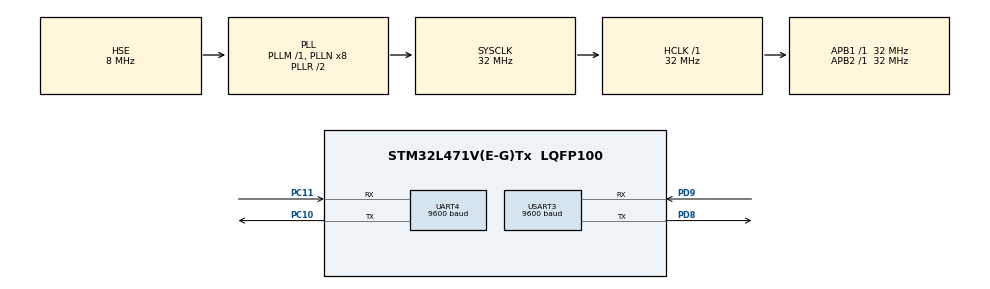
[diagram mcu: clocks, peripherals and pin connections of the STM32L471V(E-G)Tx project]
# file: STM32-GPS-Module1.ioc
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Dma.Request0=UART4_RX
Dma.UART4_RX.0.Direction=DMA_PERIPH_TO_MEMORY
Dma.UART4_RX.0.Instance=DMA2_Channel5
Dma.UART4_RX.0.MemDataAlignment=DMA_MDATAALIGN_BYTE
Dma.UART4_RX.0.MemInc=DMA_MINC_ENABLE
Dma.UART4_RX.0.Mode=DMA_CIRCULAR
Dma.UART4_RX.0.PeriphDataAlignment=DMA_PDATAALIGN_BYTE
Dma.UART4_RX.0.PeriphInc=DMA_PINC_DISABLE
Dma.UART4_RX.0.Priority=DMA_PRIORITY_VERY_HIGH
Mcu.Family=STM32L4
Mcu.Name=STM32L471V(E-G)Tx
Mcu.Package=LQFP100
NVIC.DMA2_Channel5_IRQn=true\:0\:0\:false\:false\:true\:false\:true\:true
NVIC.PriorityGroup=NVIC_PRIORITYGROUP_4
PC10.Mode=Asynchronous
PC10.Signal=UART4_TX
PC11.Mode=Asynchronous
PC11.Signal=UART4_RX
PC14-OSC32_IN\ (PC14).Mode=LSE-External-Clock-Source
PC14-OSC32_IN\ (PC14).Signal=RCC_OSC32_IN
PD8.Mode=Asynchronous
PD8.Signal=USART3_TX
PD9.Mode=Asynchronous
PD9.Signal=USART3_RX
PH0-OSC_IN\ (PH0).Mode=HSE-External-Oscillator
PH0-OSC_IN\ (PH0).Signal=RCC_OSC_IN
PH1-OSC_OUT\ (PH1).Mode=HSE-External-Oscillator
PH1-OSC_OUT\ (PH1).Signal=RCC_OSC_OUT
ProjectManager.HeapSize=0x200
ProjectManager.StackSize=0x400
ProjectManager.TargetToolchain=STM32CubeIDE
RCC.ADCFreq_Value=32000000
RCC.AHBFreq_Value=32000000
RCC.APB1Freq_Value=32000000
RCC.APB1TimFreq_Value=32000000
RCC.APB2Freq_Value=32000000
RCC.APB2TimFreq_Value=32000000
RCC.CortexFreq_Value=32000000
RCC.HCLKFreq_Value=32000000
RCC.HSE_VALUE=8000000
RCC.HSI_VALUE=16000000
RCC.LSE_VALUE=32768
RCC.MSI_VALUE=4000000
RCC.PLLSourceVirtual=RCC_PLLSOURCE_HSE
RCC.SYSCLKFreq_VALUE=32000000
RCC.SYSCLKSource=RCC_SYSCLKSOURCE_PLLCLK
RCC.VCOOutputFreq_Value=64000000
UART4.BaudRate=9600
USART3.BaudRate=9600
USART3.VirtualMode-Asynchronous=VM_ASYNC
board=custom

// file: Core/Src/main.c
/* USER CODE BEGIN Header */
/**
  ******************************************************************************
  * @file           : main.c
  * @brief          : Main program body
  ******************************************************************************
  * @attention
  *
  * Copyright (c) 2026 STMicroelectronics.
  * All rights reserved.
  *
  * This software is licensed under terms that can be found in the LICENSE file
  * in the root directory of this software component.
  * If no LICENSE file comes with this software, it is provided AS-IS.
  *
  ******************************************************************************
  */
/* USER CODE END Header */
#include "main.h"

/* USER CODE BEGIN Includes */
#include "gps.h"
/* USER CODE END Includes */

/* USER CODE BEGIN PTD */
GPS_t gps;
/* USER CODE END PTD */

UART_HandleTypeDef huart4;
UART_HandleTypeDef huart3;
DMA_HandleTypeDef hdma_uart4_rx;

void SystemClock_Config(void);
static void MX_GPIO_Init(void);
static void MX_DMA_Init(void);
static void MX_UART4_Init(void);
static void MX_USART3_UART_Init(void);

int main(void)
{

  /* MCU Configuration--------------------------------------------------------*/

  /* Reset of all peripherals, Initializes the Flash interface and the Systick. */
  HAL_Init();

  /* Configure the system clock */
  SystemClock_Config();

  /* Initialize all configured peripherals */
  MX_GPIO_Init();
  MX_DMA_Init();
  MX_UART4_Init();
  MX_USART3_UART_Init();
  /* USER CODE BEGIN 2 */
  GPS_Init(&gps, &huart4, &huart3);

  /* USER CODE END 2 */

  /* Infinite loop */
  /* USER CODE BEGIN WHILE */
  while (1)
  {
	  GPS_Task(&gps);

    /* USER CODE END WHILE */

  }
}

void SystemClock_Config(void)
{
  RCC_OscInitTypeDef RCC_OscInitStruct = {0};
  RCC_ClkInitTypeDef RCC_ClkInitStruct = {0};

  /** Configure the main internal regulator output voltage
  */
  if (HAL_PWREx_ControlVoltageScaling(PWR_REGULATOR_VOLTAGE_SCALE1) != HAL_OK)
  {
    Error_Handler();
  }

  /** Initializes the RCC Oscillators according to the specified parameters
  * in the RCC_OscInitTypeDef structure.
  */
  RCC_OscInitStruct.OscillatorType = RCC_OSCILLATORTYPE_HSE;
  RCC_OscInitStruct.HSEState = RCC_HSE_ON;
  RCC_OscInitStruct.PLL.PLLState = RCC_PLL_ON;
  RCC_OscInitStruct.PLL.PLLSource = RCC_PLLSOURCE_HSE;
  RCC_OscInitStruct.PLL.PLLM = 1;
  RCC_OscInitStruct.PLL.PLLN = 8;
  RCC_OscInitStruct.PLL.PLLP = RCC_PLLP_DIV7;
  RCC_OscInitStruct.PLL.PLLQ = RCC_PLLQ_DIV2;
  RCC_OscInitStruct.PLL.PLLR = RCC_PLLR_DIV2;
  if (HAL_RCC_OscConfig(&RCC_OscInitStruct) != HAL_OK)
  {
    Error_Handler();
  }

  /** Initializes the CPU, AHB and APB buses clocks
  */
  RCC_ClkInitStruct.ClockType = RCC_CLOCKTYPE_HCLK|RCC_CLOCKTYPE_SYSCLK
                              |RCC_CLOCKTYPE_PCLK1|RCC_CLOCKTYPE_PCLK2;
  RCC_ClkInitStruct.SYSCLKSource = RCC_SYSCLKSOURCE_PLLCLK;
  RCC_ClkInitStruct.AHBCLKDivider = RCC_SYSCLK_DIV1;
  RCC_ClkInitStruct.APB1CLKDivider = RCC_HCLK_DIV1;
  RCC_ClkInitStruct.APB2CLKDivider = RCC_HCLK_DIV1;

  if (HAL_RCC_ClockConfig(&RCC_ClkInitStruct, FLASH_LATENCY_1) != HAL_OK)
  {
    Error_Handler();
  }
}

static void MX_UART4_Init(void)
{

  huart4.Instance = UART4;
  huart4.Init.BaudRate = 9600;
  huart4.Init.WordLength = UART_WORDLENGTH_8B;
  huart4.Init.StopBits = UART_STOPBITS_1;
  huart4.Init.Parity = UART_PARITY_NONE;
  huart4.Init.Mode = UART_MODE_TX_RX;
  huart4.Init.HwFlowCtl = UART_HWCONTROL_NONE;
  huart4.Init.OverSampling = UART_OVERSAMPLING_16;
  huart4.Init.OneBitSampling = UART_ONE_BIT_SAMPLE_DISABLE;
  huart4.AdvancedInit.AdvFeatureInit = UART_ADVFEATURE_NO_INIT;
  if (HAL_UART_Init(&huart4) != HAL_OK)
  {
    Error_Handler();
  }

}

static void MX_USART3_UART_Init(void)
{

  huart3.Instance = USART3;
  huart3.Init.BaudRate = 9600;
  huart3.Init.WordLength = UART_WORDLENGTH_8B;
  huart3.Init.StopBits = UART_STOPBITS_1;
  huart3.Init.Parity = UART_PARITY_NONE;
  huart3.Init.Mode = UART_MODE_TX_RX;
  huart3.Init.HwFlowCtl = UART_HWCONTROL_NONE;
  huart3.Init.OverSampling = UART_OVERSAMPLING_16;
  huart3.Init.OneBitSampling = UART_ONE_BIT_SAMPLE_DISABLE;
  huart3.AdvancedInit.AdvFeatureInit = UART_ADVFEATURE_NO_INIT;
  if (HAL_UART_Init(&huart3) != HAL_OK)
  {
    Error_Handler();
  }

}

static void MX_DMA_Init(void)
{

  /* DMA controller clock enable */
  __HAL_RCC_DMA2_CLK_ENABLE();

  /* DMA interrupt init */
  /* DMA2_Channel5_IRQn interrupt configuration */
  HAL_NVIC_SetPriority(DMA2_Channel5_IRQn, 0, 0);
  HAL_NVIC_EnableIRQ(DMA2_Channel5_IRQn);

}

static void MX_GPIO_Init(void)
{

  /* GPIO Ports Clock Enable */
  __HAL_RCC_GPIOC_CLK_ENABLE();
  __HAL_RCC_GPIOH_CLK_ENABLE();
  __HAL_RCC_GPIOD_CLK_ENABLE();

}

void Error_Handler(void)
{
  __disable_irq();
  while (1)
  {
  }
}
